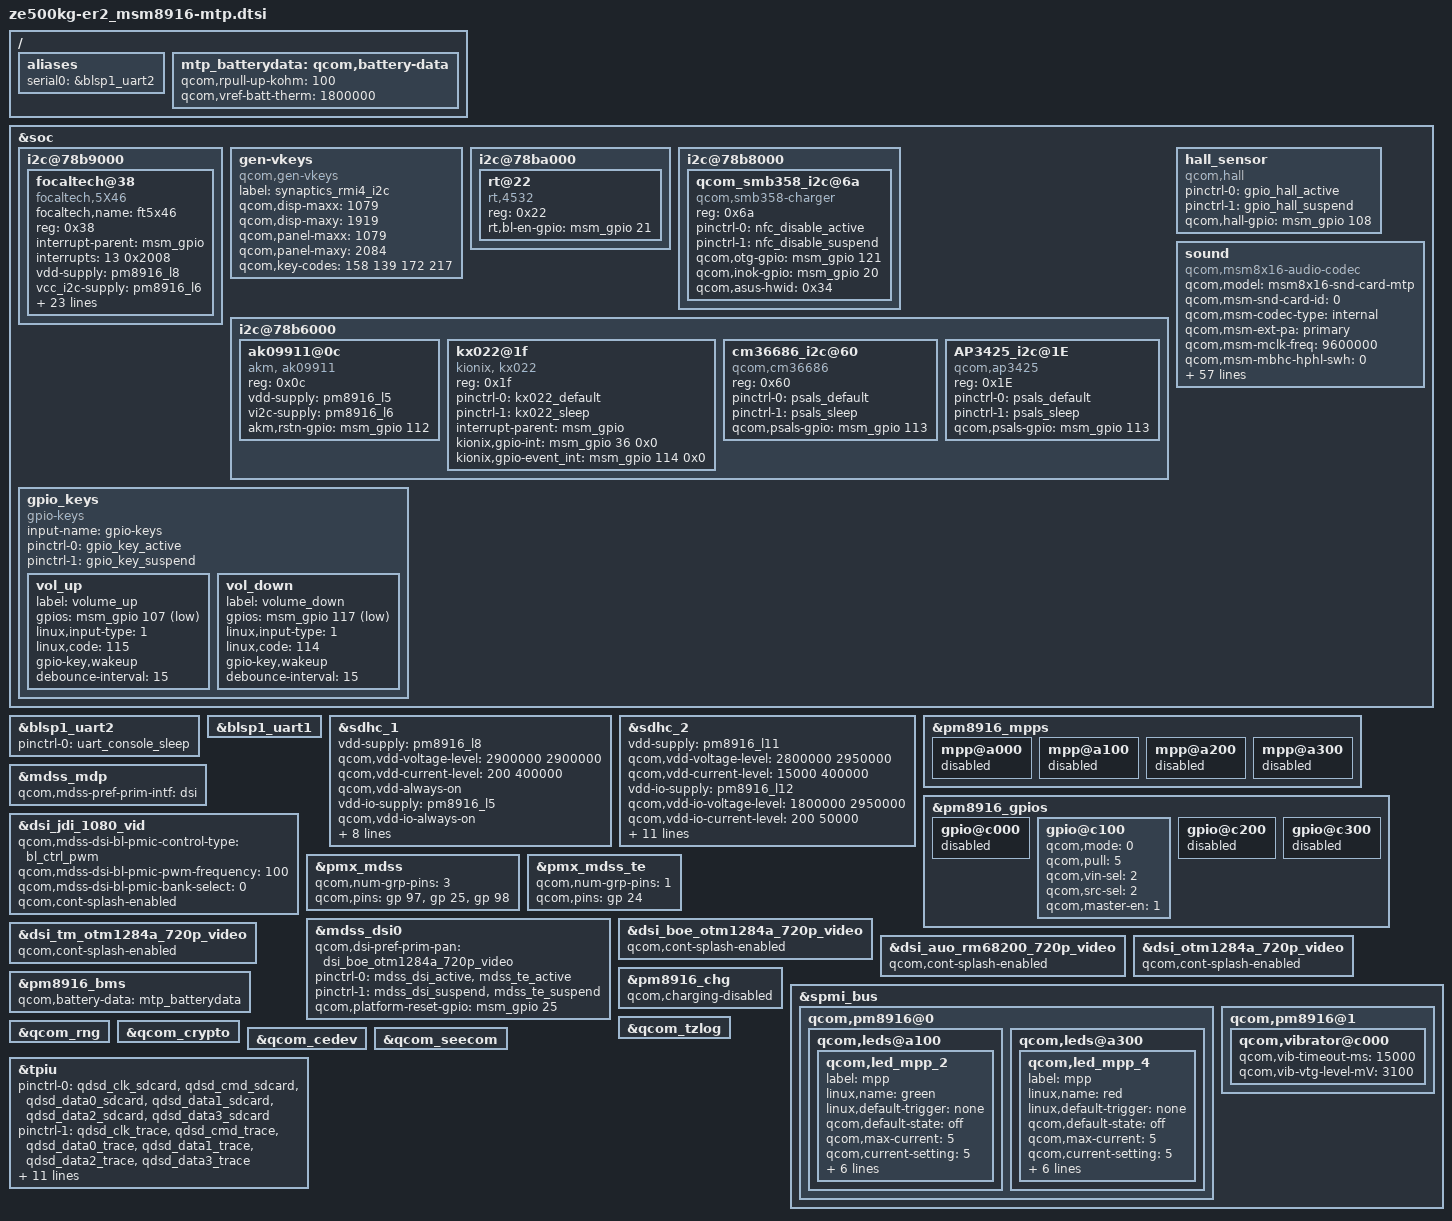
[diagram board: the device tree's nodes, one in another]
/* Copyright (c) 2014-2015, The Linux Foundation. All rights reserved.
 *
 * This program is free software; you can redistribute it and/or modify
 * it under the terms of the GNU General Public License version 2 and
 * only version 2 as published by the Free Software Foundation.
 *
 * This program is distributed in the hope that it will be useful,
 * but WITHOUT ANY WARRANTY; without even the implied warranty of
 * MERCHANTABILITY or FITNESS FOR A PARTICULAR PURPOSE.  See the
 * GNU General Public License for more details.
 */

#include "ze500kg-er2_msm8916.dtsi"
#include "ze500kg-er2_msm8916-pinctrl.dtsi"
#include "msm8916-camera-sensor-mtp.dtsi"

/ {
	aliases {
		serial0 = &blsp1_uart2;
	};
};

&soc {
	i2c@78b9000 { /* BLSP1 QUP5 */
		focaltech@38 {
			compatible = "focaltech,5X46";
			focaltech,name = "ft5x46";
			reg = <0x38>;
			interrupt-parent = <&msm_gpio>;
			interrupts = <13 0x2008>;
			vdd-supply = <&pm8916_l8>;
			vcc_i2c-supply = <&pm8916_l6>;
			/* pins used by touchscreen */
			pinctrl-names = "pmx_ts_active","pmx_ts_suspend","pmx_ts_release";
			pinctrl-0 = <&ts_int_active &ts_reset_active>;
			pinctrl-1 = <&ts_int_suspend &ts_reset_suspend>;
			pinctrl-2 = <&ts_release>;
			focaltech,family-id = <0x36>;
			focaltech,reset-gpio = <&msm_gpio 12 0x0>;
			focaltech,irq-gpio = <&msm_gpio 13 0x2008>;
			focaltech,display-coords = <0 0 720 1280>;
			focaltech,panel-coords = <0 0 720 1280>;
			focaltech,button-map= <139 102 158>;
			focaltech,no-force-update;
			focaltech,i2c-pull-up;
			focaltech,group-id = <1>;
			focaltech,hard-reset-delay-ms = <20>;
			focaltech,soft-reset-delay-ms = <200>;
			focaltech,num-max-touches = <5>;
			focaltech,fw-delay-aa-ms = <30>;
			focaltech,fw-delay-55-ms = <30>;
			focaltech,fw-upgrade-id1 = <0x79>;
			focaltech,fw-upgrade-id2 = <0x18>;
			focaltech,fw-delay-readid-ms = <10>;
			focaltech,fw-delay-era-flsh-ms = <2000>;
			focaltech,fw-auto-cal;
			focaltech,ignore-id-check;
		};
	};

	gen-vkeys {
		compatible = "qcom,gen-vkeys";
		label = "synaptics_rmi4_i2c";
		qcom,disp-maxx = <1079>;
		qcom,disp-maxy = <1919>;
		qcom,panel-maxx = <1079>;
		qcom,panel-maxy = <2084>;
		qcom,key-codes = <158 139 172 217>;
	};

	i2c@78ba000 { /* BLSP1 QUP6 */
		/* ASUS_BSP: Austin ++*/
		/*nfc-nci@e {
			compatible = "qcom,nfc-nci";
			reg = <0x0e>;
			qcom,irq-gpio = <&msm_gpio 21 0x00>;
			qcom,dis-gpio = <&msm_gpio 20 0x00>;
			qcom,clk-src = "BBCLK2";
			qcom,clk-en-gpio = <&msm_gpio 0 0x00>;
			interrupt-parent = <&msm_gpio>;
			interrupts = <21 0>;
			interrupt-names = "nfc_irq";
			pinctrl-names = "nfc_active","nfc_suspend";
			pinctrl-0 = <&nfc_int_active &nfc_disable_active>;
			pinctrl-1 = <&nfc_int_suspend &nfc_disable_suspend>;
			qcom,clk-gpio = <&pm8916_gpios 2 0>;
			clocks = <&clock_rpm clk_bb_clk2_pin>;
			clock-names = "ref_clk";
		};*/
		rt@22 {
			compatible = "rt,4532";
			reg = <0x22>;
			rt,bl-en-gpio = <&msm_gpio 21 0x00>;
		};
		/* ASUS_BSP: Austin --*/
	};

	i2c@78b8000 { /* BLSP1 QUP4 */
		/* ASUS_BSP: David: charger i2c ++*/
		qcom_smb358_i2c@6a {
			compatible = "qcom,smb358-charger";
			reg = <0x6a>;
			pinctrl-names = "smb358_nfc_disable_active","smb358_nfc_disable_suspend";
			pinctrl-0 = <&nfc_disable_active>;
			pinctrl-1 = <&nfc_disable_suspend>;
			qcom,otg-gpio = <&msm_gpio 121 0x0>;
			qcom,inok-gpio = <&msm_gpio 20 0x0>;
			qcom,asus-hwid = <0x34>;
		};
		/* ASUS_BSP: David: charger i2c --*/
	};

	i2c@78b6000 { /* BLSP1 QUP2 */
		/*  ASUS_BSP +++ Peter_Lu "Akm09911 compass sensor & KXTJ9 Gsensor" */
		ak09911@0c {
			compatible = "akm, ak09911";
			reg = <0x0c>;
			vdd-supply = <&pm8916_l5>;
			vi2c-supply = <&pm8916_l6>;
			akm,rstn-gpio = <&msm_gpio 112 0x0>;
		};
		kx022@1f {
			compatible = "kionix, kx022";
			reg = <0x1f>;
			pinctrl-names = "kx022_gpio_high","kx022_low";
			pinctrl-0 = <&kx022_default>;
			pinctrl-1 = <&kx022_sleep>;
			interrupt-parent = <&msm_gpio>;
			kionix,gpio-int = <&msm_gpio 36 0x0>;
			kionix,gpio-event_int = <&msm_gpio 114 0x0>;
		};
		/*  ASUS_BSP --- Peter_Lu "Akm09911 compass sensor & KXTJ9 Gsensor" */

		/* ASUS_BSP +++ srHuang CM36686 */
		cm36686_i2c@60 {
			compatible = "qcom,cm36686";
			reg = <0x60>;		
			pinctrl-names = "psals_gpio_high","psals_gpio_low";
			pinctrl-0 = <&psals_default>;
			pinctrl-1 = <&psals_sleep>;	
			qcom,psals-gpio = <&msm_gpio 113 0x0>;			
		};
		/* ASUS_BSP --- srHuang CM36686 */

		/* ASUS_BSP +++ srHuang AP3425 */
            AP3425_i2c@1E {
                    compatible = "qcom,ap3425";
                    reg = <0x1E>;
                    pinctrl-names = "psals_gpio_high","psals_gpio_low";
                    pinctrl-0 = <&psals_default>;
                    pinctrl-1 = <&psals_sleep>;
                    qcom,psals-gpio = <&msm_gpio 113 0x0>;
            };
            /* ASUS_BSP --- srHuang AP3425 */
	};

	// ASUS_BSP +++ srHuang HALL sensor
	hall_sensor {
		compatible = "qcom,hall";
		pinctrl-names = "hall_gpio_high","hall_gpio_low";
		pinctrl-0 = <&gpio_hall_active>;
		pinctrl-1 = <&gpio_hall_suspend>;			
		qcom,hall-gpio = <&msm_gpio 108 0x0>;
	};
	// ASUS_BSP --- srHuang HALL sensor

	sound {
		compatible = "qcom,msm8x16-audio-codec";
		qcom,model = "msm8x16-snd-card-mtp";
		qcom,msm-snd-card-id = <0>;
		qcom,msm-codec-type = "internal";
		qcom,msm-ext-pa = "primary";
		qcom,msm-mclk-freq = <9600000>;
		qcom,msm-mbhc-hphl-swh = <0>;
		qcom,msm-mbhc-gnd-swh = <0>;
		qcom,msm-hs-micbias-type = "internal";
		qcom,audio-routing =
			"RX_BIAS", "MCLK",
			"SPK_RX_BIAS", "MCLK",
			"INT_LDO_H", "MCLK",
			"MIC BIAS External", "Handset Mic",
			"MIC BIAS Internal2", "Headset Mic",
			"MIC BIAS External", "Secondary Mic",
			"AMIC1", "MIC BIAS External",
			"AMIC2", "MIC BIAS Internal2",
			"AMIC3", "MIC BIAS External",
			"DMIC1", "MIC BIAS Internal1",
			"MIC BIAS Internal1", "Digital Mic1",
			"DMIC2", "MIC BIAS Internal1",
			"MIC BIAS Internal1", "Digital Mic2";
		pinctrl-names = "cdc_lines_act",
				"cdc_lines_sus",
				"cdc_lines_sec_ext_act",
				"cdc_lines_sec_ext_sus",
				"cross_conn_det_act",
				"cross_conn_det_sus";
		pinctrl-0 = <&cdc_pdm_lines_act>;
		pinctrl-1 = <&cdc_pdm_lines_sus>;
		pinctrl-2 = <&cdc_pdm_lines_act &cdc_ext_pa_act
						&cdc_ext_pa_ws_act>;
		pinctrl-3 = <&cdc_pdm_lines_sus &cdc_ext_pa_sus
						&cdc_ext_pa_ws_sus>;
		pinctrl-4 = <&cross_conn_det_act>;
		pinctrl-5 = <&cross_conn_det_sus>;
		qcom,cdc-us-euro-gpios = <&msm_gpio 120 0>;
		asoc-platform = <&pcm0>, <&pcm1>, <&voip>, <&voice>,
				<&loopback>, <&compress>, <&hostless>,
				<&afe>, <&lsm>, <&routing>, <&lpa>;
		asoc-platform-names = "msm-pcm-dsp.0", "msm-pcm-dsp.1",
				"msm-voip-dsp", "msm-pcm-voice", "msm-pcm-loopback",
				"msm-compress-dsp", "msm-pcm-hostless", "msm-pcm-afe",
				"msm-lsm-client", "msm-pcm-routing", "msm-pcm-lpa";
		asoc-cpu = <&dai_pri_auxpcm>, <&dai_hdmi>,
				<&dai_mi2s0>, <&dai_mi2s1>, <&dai_mi2s2>, <&dai_mi2s3>,
				<&sb_0_rx>, <&sb_0_tx>, <&sb_1_rx>, <&sb_1_tx>,
				<&sb_3_rx>, <&sb_3_tx>, <&sb_4_rx>, <&sb_4_tx>,
				<&bt_sco_rx>, <&bt_sco_tx>, <&bt_a2dp_rx>,
				<&int_fm_rx>, <&int_fm_tx>,
				<&afe_pcm_rx>, <&afe_pcm_tx>, <&afe_proxy_rx>, <&afe_proxy_tx>,
				<&incall_record_rx>, <&incall_record_tx>, <&incall_music_rx>,
				<&incall_music_2_rx>;
		asoc-cpu-names = "msm-dai-q6-auxpcm.1", "msm-dai-q6-hdmi.8",
				"msm-dai-q6-mi2s.0", "msm-dai-q6-mi2s.1",
				"msm-dai-q6-mi2s.2", "msm-dai-q6-mi2s.3",
				"msm-dai-q6-dev.16384", "msm-dai-q6-dev.16385",
				"msm-dai-q6-dev.16386", "msm-dai-q6-dev.16387",
				"msm-dai-q6-dev.16390", "msm-dai-q6-dev.16391",
				"msm-dai-q6-dev.16392", "msm-dai-q6-dev.16393",
				"msm-dai-q6-dev.12288", "msm-dai-q6-dev.12289",
				"msm-dai-q6-dev.12290", "msm-dai-q6-dev.12292",
				"msm-dai-q6-dev.12293",	"msm-dai-q6-dev.224",
				"msm-dai-q6-dev.225", "msm-dai-q6-dev.241",
				"msm-dai-q6-dev.240", "msm-dai-q6-dev.32771",
				"msm-dai-q6-dev.32772", "msm-dai-q6-dev.32773",
				"msm-dai-q6-dev.32770";
		asoc-codec = <&stub_codec>, <&pm8916_tombak_dig>;
		asoc-codec-names = "msm-stub-codec.1", "tombak_codec";

		AUDIO_DEBUG = <&msm_gpio 119 0x00>; /* ASUS_BSP Paul +++ */
	};
};

&blsp1_uart2 {
	status = "ok";
	pinctrl-names = "default";
	pinctrl-0 = <&uart_console_sleep>;
};

&soc {
	gpio_keys {
		compatible = "gpio-keys";
		input-name = "gpio-keys";
		pinctrl-names = "tlmm_gpio_key_active","tlmm_gpio_key_suspend";
		pinctrl-0 = <&gpio_key_active>;
		pinctrl-1 = <&gpio_key_suspend>;

		//camera_focus {
		//	label = "camera_focus";
		//	gpios = <&msm_gpio 108 0x1>;
		//	linux,input-type = <1>;
		//	linux,code = <0x210>;
		//	gpio-key,wakeup;
		//	debounce-interval = <15>;
		//};

		//camera_snapshot {
		//	label = "camera_snapshot";
		//	gpios = <&msm_gpio 109 0x1>;
		//	linux,input-type = <1>;
		//	linux,code = <0x2fe>;
		//	gpio-key,wakeup;
		//	debounce-interval = <15>;
		//};

		vol_up {
			label = "volume_up";
			gpios = <&msm_gpio 107 0x1>;
			linux,input-type = <1>;
			linux,code = <115>;
			gpio-key,wakeup;
			debounce-interval = <15>;
		};
		/*+++ ASUS BSP Porting KEYPAD +++*/
		vol_down {
			label = "volume_down";
			gpios = <&msm_gpio 117 0x1>;
			linux,input-type = <1>;
			linux,code = <114>;
			gpio-key,wakeup;
			debounce-interval = <15>;
		};
		/*--- ASUS BSP Porting KEYPAD ---*/
	};
};

&blsp1_uart1 {
	status = "ok";
};

&sdhc_1 {
	vdd-supply = <&pm8916_l8>;
	qcom,vdd-voltage-level = <2900000 2900000>;
	qcom,vdd-current-level = <200 400000>;
	qcom,vdd-always-on;		/*ASUS_BSP Deeo : make sure eMMC VDD alawys on even suspend*/

	vdd-io-supply = <&pm8916_l5>;
	qcom,vdd-io-always-on;
	qcom,vdd-io-lpm-sup;
	qcom,vdd-io-voltage-level = <1800000 1800000>;
	qcom,vdd-io-current-level = <200 60000>;

	pinctrl-names = "active", "sleep";
	pinctrl-0 = <&sdc1_clk_on &sdc1_cmd_on &sdc1_data_on>;
	pinctrl-1 = <&sdc1_clk_off &sdc1_cmd_off &sdc1_data_off>;

	qcom,nonremovable;

	status = "ok";
};

&sdhc_2 {
	vdd-supply = <&pm8916_l11>;
	qcom,vdd-voltage-level = <2800000 2950000>;
	qcom,vdd-current-level = <15000 400000>;

	vdd-io-supply = <&pm8916_l12>;
	qcom,vdd-io-voltage-level = <1800000 2950000>;
	qcom,vdd-io-current-level = <200 50000>;

	pinctrl-names = "active", "sleep";
	pinctrl-0 = <&sdc2_clk_on &sdc2_cmd_on &sdc2_data_on &sdc2_cd_on>;
	pinctrl-1 = <&sdc2_clk_off &sdc2_cmd_off &sdc2_data_off &sdc2_cd_off>;

	#address-cells = <0>;
	interrupt-parent = <&sdhc_2>;
	interrupts = <0 1 2>;
	#interrupt-cells = <1>;
	interrupt-map-mask = <0xffffffff>;
	interrupt-map = <0 &intc 0 125 0
			1 &intc 0 221 0
			2 &msm_gpio 38 0>;
	interrupt-names = "hc_irq", "pwr_irq", "status_irq";
	cd-gpios = <&msm_gpio 38 0x1>;
	en-gpios = <&msm_gpio 118 0x1>;	//ASUS_BSP Deeo : replace L11 enable pin +++

	status = "ok";
};

&pm8916_mpps {
	mpp@a000 { /* MPP 1 */
		/* VDD_PX */
		status = "disabled";
	};

	mpp@a100 { /* MPP 2 */
		/* HR LED */
		status = "disabled";
	};

	mpp@a200 { /* MPP 3 */
		/* VREF DAC */
		status = "disabled";
	};

	mpp@a300 { /* MPP 4 */
		//ASUS_BSP : disable BL use MPP4 +++
		/* Backlight PWM */
		//qcom,mode = <1>;		/* Digital output */
		//qcom,invert = <0>;		/* Disable invert */
		//qcom,src-sel = <4>;		/* DTEST1 */
		//qcom,vin-sel = <0>;		/* VPH_PWR */
		//qcom,master-en = <1>;		/* Enable MPP */
		status = "disabled";
		//ASUS_BSP : disable BL use MPP4 ---
	};
};

&pm8916_gpios {
	gpio@c000 { /* GPIO 1 */
		/* Battery UICC Alarm */
		status = "disabled";
	};

	gpio@c100 { /* GPIO 2 */
		/* NFC_CLK_REQ */
		qcom,mode = <0>; /* QPNP_PIN_MODE_DIG_IN */
		qcom,pull = <5>; /* QPNP_PIN_PULL_NO */
		qcom,vin-sel = <2>; /* QPNP_PIN_VIN2 */
		qcom,src-sel = <2>; /* QPNP_PIN_SEL_FUNC_1 */
		qcom,master-en = <1>;
	};

	gpio@c200 { /* GPIO 3 */
		/* External regulator control for WTR */
		status = "disabled";
	};

	gpio@c300 { /* GPIO 4 */
		/* External regulator control for APC */
		status = "disabled";
	};
};

#include "dsi-panel-jdi-1080p-video.dtsi"
 /* ASUS_BSP: Bernard ++  */
#include "dsi-panel-otm1284a-720p-video.dtsi"
#include "dsi-panel-auo-rm68200-720p-video-otp.dtsi"
#include "dsi-panel-tm-otm1284a-720p-video-otp.dtsi"
#include "dsi-panel-boe-otm1284a-720p-video-otp.dtsi"
 /* ASUS_BSP: Bernard --  */

&mdss_mdp {
	qcom,mdss-pref-prim-intf = "dsi";
};

/* ASUS_BSP: Bernard ++ */
/*&dsi_otm1284a_720p_video {
	qcom,mdss-dsi-bl-pmic-control-type = "bl_ctrl_pwm";
	qcom,mdss-dsi-bl-pmic-pwm-frequency = <100>;
	qcom,mdss-dsi-bl-pmic-bank-select = <0>;
	//qcom,mdss-dsi-pwm-gpio = <&pm8916_mpps 4 0>;		//ASUS_BSP : disable BL use MPP4

};*/
/* ASUS_BSP: Bernard -- */

&dsi_jdi_1080_vid {
	qcom,mdss-dsi-bl-pmic-control-type = "bl_ctrl_pwm";
	qcom,mdss-dsi-bl-pmic-pwm-frequency = <100>;
	qcom,mdss-dsi-bl-pmic-bank-select = <0>;
	//qcom,mdss-dsi-pwm-gpio = <&pm8916_mpps 4 0>;		//ASUS_BSP : disable BL use MPP4

};

&pmx_mdss {
	qcom,num-grp-pins = <3>;
	qcom,pins = <&gp 97>, <&gp 25>, <&gp 98>;
};

&pmx_mdss_te {
	qcom,num-grp-pins = <1>;
	qcom,pins = <&gp 24>;
};

/* ASUS_BSP: Bernard ++ */
&mdss_dsi0 {
	qcom,dsi-pref-prim-pan = <&dsi_auo_rm68200_720p_video>;
	qcom,dsi-pref-prim-pan = <&dsi_otm1284a_720p_video>;
	qcom,dsi-pref-prim-pan = <&dsi_tm_otm1284a_720p_video>;
	qcom,dsi-pref-prim-pan = <&dsi_boe_otm1284a_720p_video>;
	pinctrl-names = "mdss_default", "mdss_sleep";
	pinctrl-0 = <&mdss_dsi_active &mdss_te_active>;
	pinctrl-1 = <&mdss_dsi_suspend &mdss_te_suspend>;

	/*qcom,platform-enable-gpio = <&msm_gpio 97 0>;*/
	qcom,platform-reset-gpio = <&msm_gpio 25 0>;
	/*qcom,platform-bklight-en-gpio = <&msm_gpio 21 0>;*/
};

&dsi_boe_otm1284a_720p_video {
       qcom,cont-splash-enabled;
};

&dsi_tm_otm1284a_720p_video {
       qcom,cont-splash-enabled;
};

&dsi_auo_rm68200_720p_video {
       qcom,cont-splash-enabled;
};

&dsi_otm1284a_720p_video {
       qcom,cont-splash-enabled;
};
/* ASUS_BSP: Bernard -- */

&dsi_jdi_1080_vid {
       qcom,cont-splash-enabled;
};

&pm8916_chg {
	status = "ok";
	qcom,charging-disabled;
};

/ {
	mtp_batterydata: qcom,battery-data {
		qcom,rpull-up-kohm = <100>;
		qcom,vref-batt-therm = <1800000>;

		//#include "batterydata-palladium.dtsi"
		// bsp weiyu  add new batt. +++
		#include "batterydata-NVT.dtsi"
		#include "batterydata-Coslight2400_id300k.dtsi"	
		#include "batterydata-PAN-SMP.dtsi"
		#include "batterydata-Coslight.dtsi"
		// bsp weiyu  add new batt. ---
	};
};

&pm8916_bms {
	status = "ok";
	qcom,battery-data = <&mtp_batterydata>;
};

&spmi_bus {
	qcom,pm8916@0 {
		//ASUS_BSP Austin_T : Enable LED driver +++
		qcom,leds@a100 {
			status = "okay";
			qcom,led_mpp_2 {
				label = "mpp";
				linux,name = "green";
				linux,default-trigger = "none";
				qcom,default-state = "off";
				qcom,max-current = <5>;
				qcom,current-setting = <5>;
				qcom,id = <6>;
				qcom,mode = "pwm";
				qcom,source-sel = <8>;
				qcom,mode-ctrl = <0x60>;
				pwms = <&pm8916_pwm 0 0>;
				qcom,pwm-us = <100>; //setup 0.0001s pwm output
			};
		};
		qcom,leds@a300 {
			status = "okay";
			qcom,led_mpp_4 {
				label = "mpp";
				linux,name = "red";
				linux,default-trigger = "none";
				qcom,default-state = "off";
				qcom,max-current = <5>;
				qcom,current-setting = <5>;
				qcom,id = <6>;
				qcom,mode = "pwm";
				qcom,source-sel = <8>;
				qcom,mode-ctrl = <0x60>;
				pwms = <&pm8916_pwm 0 0>;
				qcom,pwm-us = <100>; //setup 0.0001s pwm output
			};
		};
		//ASUS_BSP Austin_T : Enable LED driver ---
	};
};

&qcom_tzlog {
	status = "okay";
};

&qcom_rng {
	status = "okay";
};

&qcom_crypto {
	status = "okay";
};

&qcom_cedev {
	status = "okay";
};

&qcom_seecom {
	status = "okay";
};

/* CoreSight */
&tpiu {
      pinctrl-names = "sdcard", "trace", "swduart",
		      "swdtrc", "jtag", "spmi";
       /* NIDnT */
      pinctrl-0 = <&qdsd_clk_sdcard &qdsd_cmd_sdcard
                  &qdsd_data0_sdcard &qdsd_data1_sdcard
                  &qdsd_data2_sdcard &qdsd_data3_sdcard>;
      pinctrl-1 = <&qdsd_clk_trace &qdsd_cmd_trace
                  &qdsd_data0_trace &qdsd_data1_trace
                  &qdsd_data2_trace &qdsd_data3_trace>;
      pinctrl-2 = <&qdsd_cmd_swduart &qdsd_data0_swduart
                  &qdsd_data1_swduart &qdsd_data2_swduart
                  &qdsd_data3_swduart>;
      pinctrl-3 = <&qdsd_clk_swdtrc &qdsd_cmd_swdtrc
                  &qdsd_data0_swdtrc &qdsd_data1_swdtrc
                  &qdsd_data2_swdtrc &qdsd_data3_swdtrc>;
      pinctrl-4 = <&qdsd_cmd_jtag &qdsd_data0_jtag
                  &qdsd_data1_jtag &qdsd_data2_jtag
                  &qdsd_data3_jtag>;
      pinctrl-5 = <&qdsd_clk_spmi &qdsd_cmd_spmi
                  &qdsd_data0_spmi &qdsd_data3_spmi>;
};

&spmi_bus {
	qcom,pm8916@1 {
		qcom,vibrator@c000 {
			status = "okay";
			qcom,vib-timeout-ms = <15000>;
			qcom,vib-vtg-level-mV = <3100>;
		};
	};
};
